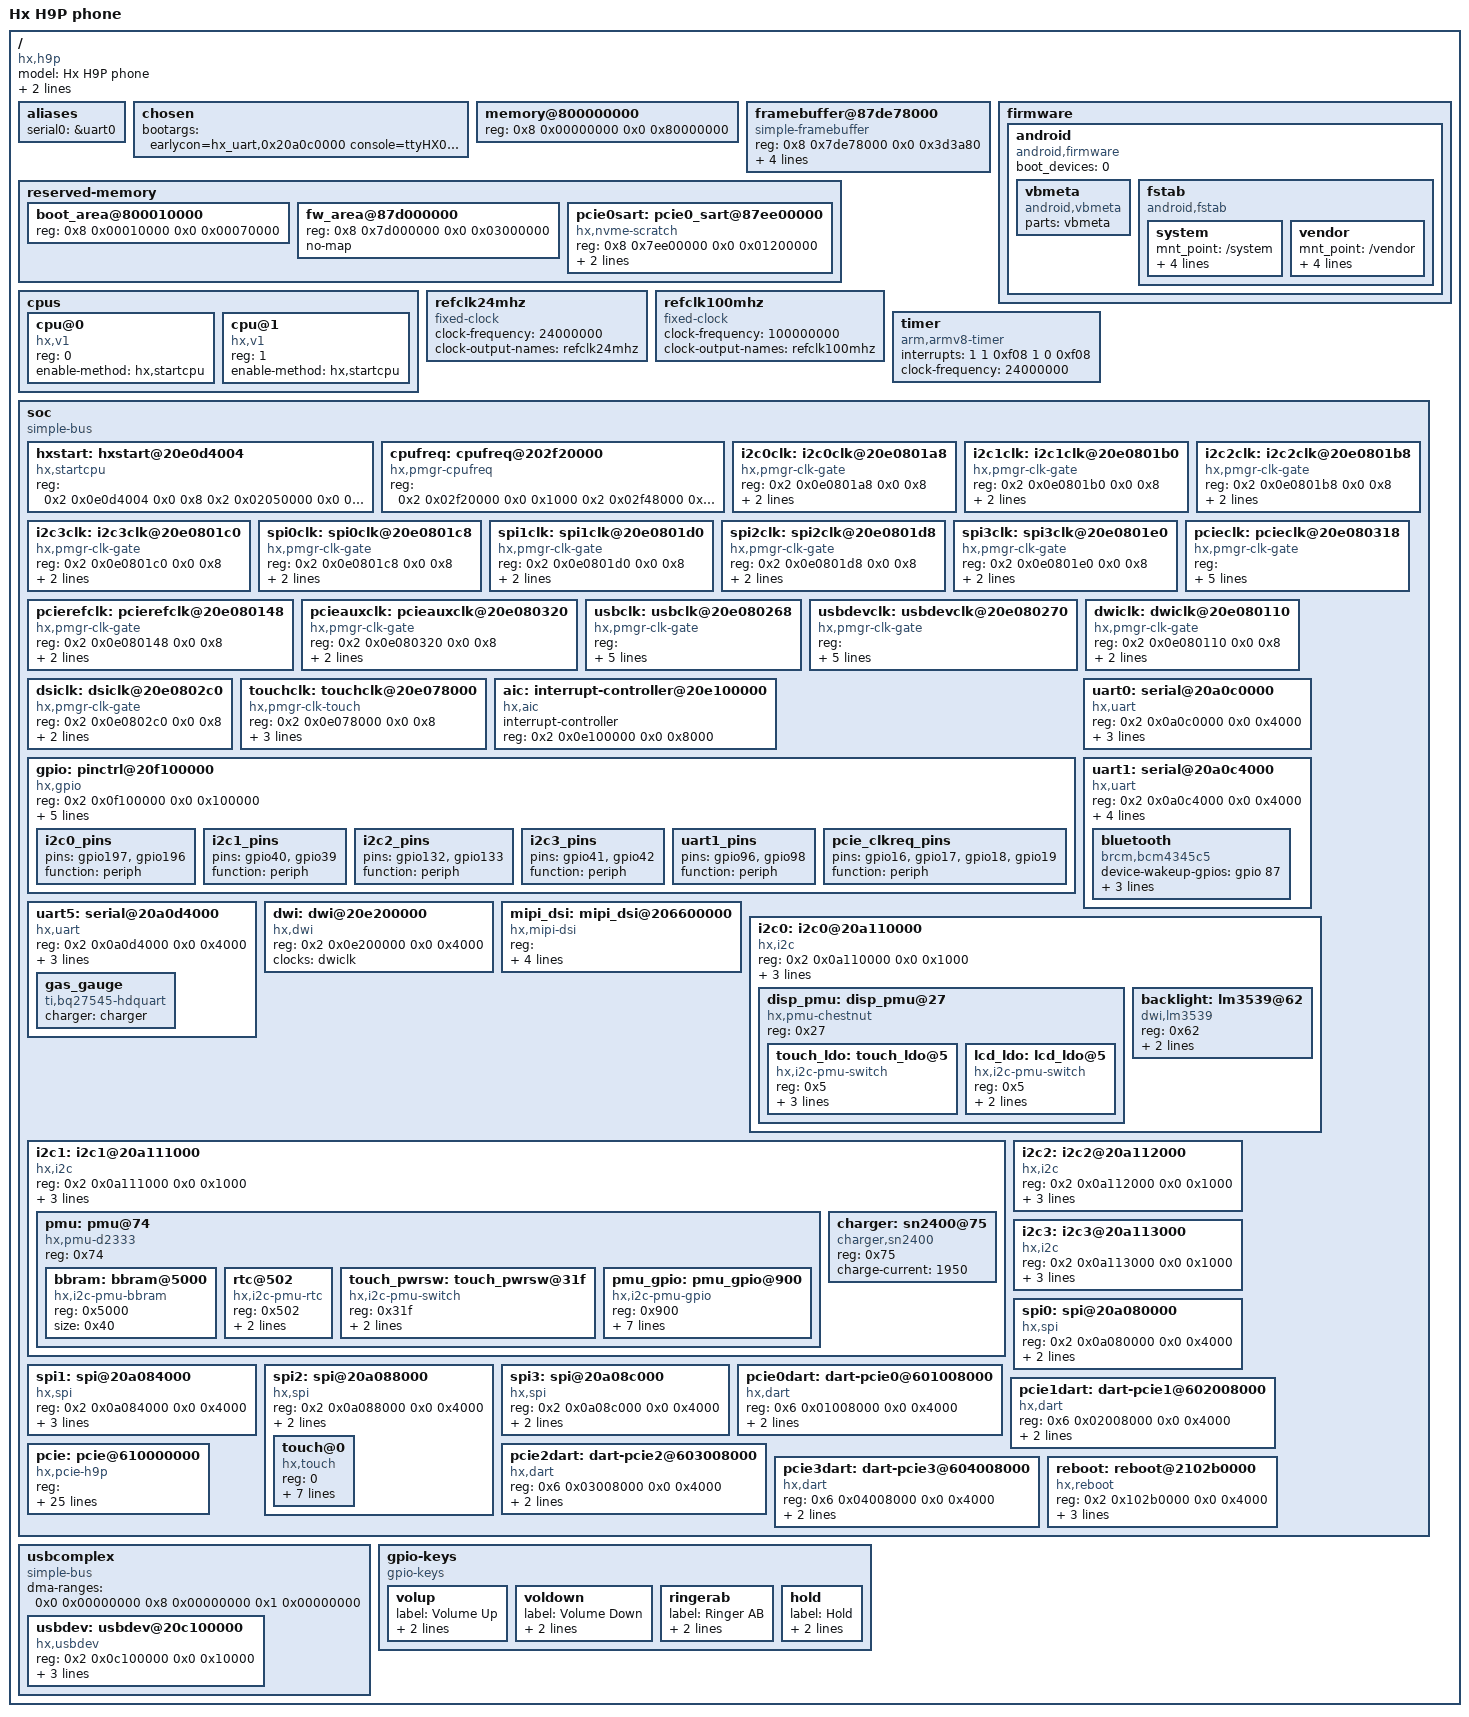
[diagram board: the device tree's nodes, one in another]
/dts-v1/;

/ {
    model = "Hx H9P phone";
    compatible = "hx,h9p";

    hardware-model = "D101";

    interrupt-parent = <&aic>;
    #address-cells = <2>;
    #size-cells = <2>;

    aliases {
        serial0 = &uart0;
    };

    chosen {
        bootargs = "earlycon=hx_uart,0x20a0c0000 console=ttyHX0 console=tty0 selinux=1 enforcing=0";
    };

    memory@800000000 {
        device_type = "memory";
        reg = <0x8 0x00000000 0x0 0x80000000>;
    };

    framebuffer@87de78000 {
        compatible = "simple-framebuffer";
        reg = <0x8 0x7de78000 0x0 0x3d3a80>;
        format = "a8b8g8r8";
        height = <0x536>;
        stride = <0xbc0>;
        width = <0x2ee>;
        status = "okay";
    };

    reserved-memory {
        #address-cells = <0x2>;
        #size-cells = <0x2>;
        ranges;

        boot_area@800010000 {
            reg = <0x8 0x00010000 0x0 0x00070000>;
        };

        fw_area@87d000000 {
            reg = <0x8 0x7d000000 0x0 0x03000000>;
            no-map;
        };

        pcie0sart: pcie0_sart@87ee00000 {
            compatible = "hx,nvme-scratch";
            reg = <0x8 0x7ee00000 0x0 0x01200000>;
            iova = <0xbc000000>;
            no-map;
        };
    };

    firmware {
        android {
            compatible = "android,firmware";
            boot_devices = "0";
//            boot_devices = "soc/610000000.pcie";

            vbmeta {
                compatible = "android,vbmeta";
                parts = "vbmeta";
            };

            fstab {
                compatible = "android,fstab";

                system {
                    mnt_point = "/system";
                    dev = "system";
                    type = "ext4";
                    mnt_flags = "ro";
                    fsmgr_flags = "wait,logical";
                    status = "ok";
                };

                vendor {
                    mnt_point = "/vendor";
                    dev = "vendor";
                    type = "ext4";
                    mnt_flags = "ro";
                    fsmgr_flags = "wait,logical";
                    status = "ok";
                };
            };
        };
    };

    cpus {
        #address-cells = <1>;
        #size-cells = <0>;

        cpu@0 {
            device_type = "cpu";
            compatible = "hx,v1";
            reg = <0>;
            enable-method = "hx,startcpu";
        };

        cpu@1 {
            device_type = "cpu";
            compatible = "hx,v1";
            reg = <1>;
            enable-method = "hx,startcpu";
        };
    };

    refclk24mhz: refclk24mhz {
        compatible = "fixed-clock";
        #clock-cells = <0>;
        clock-frequency = <24000000>;
        clock-output-names = "refclk24mhz";
    };

    refclk100mhz: refclk100mhz {
        compatible = "fixed-clock";
        #clock-cells = <0>;
        clock-frequency = <100000000>;
        clock-output-names = "refclk100mhz";
    };

    timer {
        compatible = "arm,armv8-timer";
        interrupts = <1 1 0xf08   1 0 0xf08>;
        clock-frequency = <24000000>;
    };

    soc {
        compatible = "simple-bus";
        #address-cells = <2>;
        #size-cells = <2>;
        ranges;

        hxstart: hxstart@20e0d4004 {
            compatible = "hx,startcpu";
            reg = <0x2 0x0e0d4004 0x0 0x8   0x2 0x02050000 0x0 0x8   0x2 0x02030fb0 0x0 0x4
                   0x2 0x0e0d4004 0x0 0x8   0x2 0x02150000 0x0 0x8   0x2 0x02130fb0 0x0 0x4>;
        };

        cpufreq: cpufreq@202f20000 {
            compatible = "hx,pmgr-cpufreq";
            reg = <0x2 0x02f20000 0x0 0x1000   0x2 0x02f48000 0x0 0x1000   0x2 0x02f50000 0x0 0x1000
                   0x2 0x02f80000 0x0 0x1000   0x2 0x0e068000 0x0 0x1000   0x2 0x0e09c000 0x0 0x1000
                   0x2 0x0e0a0000 0x0 0x1000   0x2 0x0e0c8000 0x0 0x1000>;
        };

        i2c0clk: i2c0clk@20e0801a8 {
            compatible = "hx,pmgr-clk-gate";
            #clock-cells = <0>;
            reg = <0x2 0x0e0801a8 0x0 0x8>;
            clocks = <&refclk24mhz>;
            clock-output-names = "i2c0clk";
        };

        i2c1clk: i2c1clk@20e0801b0 {
            compatible = "hx,pmgr-clk-gate";
            #clock-cells = <0>;
            reg = <0x2 0x0e0801b0 0x0 0x8>;
            clocks = <&refclk24mhz>;
            clock-output-names = "i2c1clk";
        };

        i2c2clk: i2c2clk@20e0801b8 {
            compatible = "hx,pmgr-clk-gate";
            #clock-cells = <0>;
            reg = <0x2 0x0e0801b8 0x0 0x8>;
            clocks = <&refclk24mhz>;
            clock-output-names = "i2c2clk";
        };

        i2c3clk: i2c3clk@20e0801c0 {
            compatible = "hx,pmgr-clk-gate";
            #clock-cells = <0>;
            reg = <0x2 0x0e0801c0 0x0 0x8>;
            clocks = <&refclk24mhz>;
            clock-output-names = "i2c3clk";
        };

        spi0clk: spi0clk@20e0801c8 {
            compatible = "hx,pmgr-clk-gate";
            #clock-cells = <0>;
            reg = <0x2 0x0e0801c8 0x0 0x8>;
            clocks = <&refclk24mhz>;
            clock-output-names = "spi0clk";
        };

        spi1clk: spi1clk@20e0801d0 {
            compatible = "hx,pmgr-clk-gate";
            #clock-cells = <0>;
            reg = <0x2 0x0e0801d0 0x0 0x8>;
            clocks = <&refclk24mhz>;
            clock-output-names = "spi1clk";
        };

        spi2clk: spi2clk@20e0801d8 {
            compatible = "hx,pmgr-clk-gate";
            #clock-cells = <0>;
            reg = <0x2 0x0e0801d8 0x0 0x8>;
            clocks = <&refclk24mhz>;
            clock-output-names = "spi2clk";
        };

        spi3clk: spi3clk@20e0801e0 {
            compatible = "hx,pmgr-clk-gate";
            #clock-cells = <0>;
            reg = <0x2 0x0e0801e0 0x0 0x8>;
            clocks = <&refclk24mhz>;
            clock-output-names = "spi3clk";
        };

        pcieclk: pcieclk@20e080318 {
            compatible = "hx,pmgr-clk-gate";
            #clock-cells = <0>;
            reg = <0x2 0x0e080318 0x0 0x8
                   0x6 0x00010000 0x0 0x8000>;
            clocks = <&refclk100mhz>;
            clock-output-names = "pcieclk";
            post-up = <1 0x0000 0x00000007   1 0x000c 0x80010005   1 0x4104 0x00000003   1 0x4100 0x00000003>;
        };

        pcierefclk: pcierefclk@20e080148 {
            compatible = "hx,pmgr-clk-gate";
            #clock-cells = <0>;
            reg = <0x2 0x0e080148 0x0 0x8>;
            clocks = <&refclk100mhz>;
            clock-output-names = "pcierefclk";
        };

        pcieauxclk: pcieauxclk@20e080320 {
            compatible = "hx,pmgr-clk-gate";
            #clock-cells = <0>;
            reg = <0x2 0x0e080320 0x0 0x8>;
            clocks = <&refclk100mhz>;
            clock-output-names = "pcieauxclk";
        };

        usbclk: usbclk@20e080268 {
            compatible = "hx,pmgr-clk-gate";
            #clock-cells = <0>;
            reg = <0x2 0x0e080268 0x0 0x8
                   0x2 0x0cb00000 0x0 0x20>;
            clocks = <&refclk24mhz>;
            clock-output-names = "usbclk";
            post-up = <1 0x00 0x00000000   1 0x04 0x00000000   1 0x08 0x00003f3f   1 0x0c 0x00003f3f   1 0x10 0x0000010c>;
        };

        usbdevclk: usbdevclk@20e080270 {
            compatible = "hx,pmgr-clk-gate";
            #clock-cells = <0>;
            reg = <0x2 0x0e080270 0x0 0x8
                   0x2 0x0c900000 0x0 0x100>;
            clocks = <&usbclk>;
            clock-output-names = "usbdevclk";
            post-up = <1 0x001c 0x00000108   1 0x003c 0x00000000   1 0x005c 0x00000108>; /* set DMA offsets for USB cores */
        };

        dwiclk: dwiclk@20e080110 {
            compatible = "hx,pmgr-clk-gate";
            #clock-cells = <0>;
            reg = <0x2 0x0e080110 0x0 0x8>;
            clocks = <&refclk24mhz>;
            clock-output-names = "dwiclk";
        };

        dsiclk: dsiclk@20e0802c0 {
            compatible = "hx,pmgr-clk-gate";
            #clock-cells = <0>;
            reg = <0x2 0x0e0802c0 0x0 0x8>;
            clocks = <&refclk100mhz>;
            clock-output-names = "dsiclk";
        };

        touchclk: touchclk@20e078000 {
            compatible = "hx,pmgr-clk-touch";
            #clock-cells = <0>;
            reg = <0x2 0x0e078000 0x0 0x8>;
            clocks = <&refclk24mhz>;
            clock-output-names = "touchclk";
            clock-frequency = <32768>;
        };

        aic: interrupt-controller@20e100000 {
            compatible = "hx,aic";
            #interrupt-cells = <3>;
            interrupt-controller;
            reg = <0x2 0x0e100000 0x0 0x8000>;
        };

        gpio: pinctrl@20f100000 {
            compatible = "hx,gpio";
            reg = <0x2 0x0f100000 0x0 0x100000>;
            pin-count = <224>;

            interrupts = <0 42 4   0 43 4   0 44 4   0 45 4   0 46 4   0 47 4   0 48 4>;

            gpio-controller;
            #gpio-cells = <2>;

            interrupt-controller;
            #interrupt-cells = <2>;

            i2c0_pins: i2c0_pins {
                pins = "gpio197", "gpio196";
                function = "periph";
            };

            i2c1_pins: i2c1_pins {
                pins = "gpio40", "gpio39";
                function = "periph";
            };

            i2c2_pins: i2c2_pins {
                pins = "gpio132", "gpio133";
                function = "periph";
            };

            i2c3_pins: i2c3_pins {
                pins = "gpio41", "gpio42";
                function = "periph";
            };

            uart1_pins: uart1_pins {
                pins = "gpio96", "gpio98";
                function = "periph";
            };

            pcie_clkreq_pins: pcie_clkreq_pins {
                pins = "gpio16", "gpio17", "gpio18", "gpio19";
                function = "periph";
            };
        };

        uart0: serial@20a0c0000 {
            compatible = "hx,uart";
            reg = <0x2 0x0a0c0000 0x0 0x4000>;
            interrupts = <0 218 4>;
            clocks = <&refclk24mhz>;
            clock-names = "refclk";
            index = <0>;
        };

        uart1: serial@20a0c4000 {
            compatible = "hx,uart";
            reg = <0x2 0x0a0c4000 0x0 0x4000>;
            interrupts = <0 219 4>;
            clocks = <&refclk24mhz>;
            clock-names = "refclk";
            index = <1>;
            pinctrl-0 = <&uart1_pins>;
            pinctrl-names = "default";

            bluetooth {
                compatible = "brcm,bcm4345c5";
                device-wakeup-gpios = <&gpio 87 0>;
                host-wakeup-gpios = <&pmu_gpio 11 0>;
                shutdown-gpios = <&pmu_gpio 8 0>;
                max-speed = <1500000>;
            };
        };

        uart5: serial@20a0d4000 {
            compatible = "hx,uart";
            reg = <0x2 0x0a0d4000 0x0 0x4000>;
            interrupts = <0 223 4>;
            clocks = <&refclk24mhz>;
            clock-names = "refclk";
            index = <5>;

            gas_gauge: gas_gauge {
                compatible = "ti,bq27545-hdquart";
                charger = <&charger>;
            };
        };

        dwi: dwi@20e200000 {
            compatible = "hx,dwi";
            reg = <0x2 0x0e200000 0x0 0x4000>;
            clocks = <&dwiclk>;
        };

        mipi_dsi: mipi_dsi@206600000 {
            compatible = "hx,mipi-dsi";
            reg = <0x2 0x06600000 0x0 0x100000   0x2 0x06400000 0x0 0x1000   0x2 0x0e0802c0 0x0 0x4>;
            clocks = <&dsiclk>;
            reset-gpios = <&gpio 172 0>;
            supply-name = "lcd_ldo";
        };

        i2c0: i2c0@20a110000 {
            compatible = "hx,i2c";
            reg = <0x2 0x0a110000 0x0 0x1000>;
            interrupts = <0 232 4>;
            clocks = <&i2c0clk>;
            pinctrl-0 = <&i2c0_pins>;
            pinctrl-names = "default";
            #address-cells = <0x1>;
            #size-cells = <0x0>;

            disp_pmu: disp_pmu@27 {
                compatible = "hx,pmu-chestnut";
                reg = <0x27>;
                #address-cells = <0x1>;
                #size-cells = <0x0>;

                touch_ldo: touch_ldo@5 {
                    compatible = "hx,i2c-pmu-switch";
                    reg = <0x5>;
                    mask = <0x10>;
                    enable = <0x10>;
                    supply-name = "mipi_dsi";
                };

                lcd_ldo: lcd_ldo@5 {
                    compatible = "hx,i2c-pmu-switch";
                    reg = <0x5>;
                    mask = <0x0F>;
                    enable = <0x0F>;
                };
            };

            backlight: lm3539@62 {
                compatible = "dwi,lm3539";
                reg = <0x62>;
                dwi = <&dwi>;
                lcd-supply = <&mipi_dsi>;
            };
        };

        i2c1: i2c1@20a111000 {
            compatible = "hx,i2c";
            reg = <0x2 0x0a111000 0x0 0x1000>;
            interrupts = <0 233 4>;
            clocks = <&i2c1clk>;
            pinctrl-0 = <&i2c1_pins>;
            pinctrl-names = "default";
            #address-cells = <0x1>;
            #size-cells = <0x0>;

            pmu: pmu@74 {
                compatible = "hx,pmu-d2333";
                reg = <0x74>;
                #address-cells = <0x1>;
                #size-cells = <0x0>;

                bbram: bbram@5000 {
                    compatible = "hx,i2c-pmu-bbram";
                    reg = <0x5000>;
                    size = <0x40>;
                };

                rtc@502 {
                    compatible = "hx,i2c-pmu-rtc";
                    reg = <0x502>;
                    nvmem = <&bbram>;
                    nvmem-offset = <0x4>;
                };

                touch_pwrsw: touch_pwrsw@31f {
                    compatible = "hx,i2c-pmu-switch";
                    reg = <0x31f>;
                    mask = <0x1>;
                    enable = <0x1>;
                };

                pmu_gpio: pmu_gpio@900 {
                    compatible = "hx,i2c-pmu-gpio";
                    reg = <0x900>;
                    reg-offs = <0x00 0x02 0x04 0x06 0x08 0x0a 0x0c 0x0e
                                0x10 0x12 0x14 0x16 0x18 0x1a 0x1c 0x1e
                                0x20 0x27 0x2d 0x33 0x39>;
                    reg-input = <0x186>;
                    bit-outval = <0x01 0x01>;
                    bit-direction = <0xc0 0x00 0x80>;

                    gpio-controller;
                    #gpio-cells = <2>;
                    gpio-base = <224>;
                };
            };

            charger: sn2400@75 {
                compatible = "charger,sn2400";
                reg = <0x75>;
                charge-current = <1950>;
            };
        };

        i2c2: i2c2@20a112000 {
            compatible = "hx,i2c";
            reg = <0x2 0x0a112000 0x0 0x1000>;
            interrupts = <0 234 4>;
            clocks = <&i2c2clk>;
            pinctrl-0 = <&i2c2_pins>;
            pinctrl-names = "default";
            #address-cells = <0x1>;
            #size-cells = <0x0>;
        };

        i2c3: i2c3@20a113000 {
            compatible = "hx,i2c";
            reg = <0x2 0x0a113000 0x0 0x1000>;
            interrupts = <0 235 4>;
            clocks = <&i2c3clk>;
            pinctrl-0 = <&i2c3_pins>;
            pinctrl-names = "default";
            #address-cells = <0x1>;
            #size-cells = <0x0>;
        };

        spi0: spi@20a080000 {
            compatible = "hx,spi";
            reg = <0x2 0x0a080000 0x0 0x4000>;
            interrupts = <0 214 4>;
            clocks = <&spi0clk>;
            #address-cells = <1>;
            #size-cells = <0>;
        };

        spi1: spi@20a084000 {
            compatible = "hx,spi";
            reg = <0x2 0x0a084000 0x0 0x4000>;
            interrupts = <0 215 4>;
            clocks = <&spi1clk>;
            cs-gpios = <&gpio 131 0   &gpio 177 0>;
            #address-cells = <1>;
            #size-cells = <0>;
        };

        spi2: spi@20a088000 {
            compatible = "hx,spi";
            reg = <0x2 0x0a088000 0x0 0x4000>;
            interrupts = <0 216 4>;
            clocks = <&spi2clk>;
            #address-cells = <1>;
            #size-cells = <0>;

            touch@0 {
                compatible = "hx,touch";
                reg = <0>;
                spi-max-frequency = <3000000>;
                hv-supply = <&touch_ldo>;
                core-supply = <&touch_pwrsw>;
                reset-gpios = <&gpio 161 0>;
                cs-gpios = <&gpio 81 0>;
                irq-gpios = <&gpio 166 1>;
                clocks = <&touchclk>;
            };
        };

        spi3: spi@20a08c000 {
            compatible = "hx,spi";
            reg = <0x2 0x0a08c000 0x0 0x4000>;
            interrupts = <0 217 4>;
            clocks = <&spi3clk>;
            #address-cells = <1>;
            #size-cells = <0>;
        };

        pcie0dart: dart-pcie0@601008000 {
            compatible = "hx,dart";
            reg = <0x6 0x01008000 0x0 0x4000>;
            interrupts = <0 271 4>;
            pcie-dart;
            #iommu-cells = <1>;
        };

        pcie1dart: dart-pcie1@602008000 {
            compatible = "hx,dart";
            reg = <0x6 0x02008000 0x0 0x4000>;
            interrupts = <0 274 4>;
            pcie-dart;
            #iommu-cells = <1>;
        };

        pcie2dart: dart-pcie2@603008000 {
            compatible = "hx,dart";
            reg = <0x6 0x03008000 0x0 0x4000>;
            interrupts = <0 277 4>;
            pcie-dart;
            #iommu-cells = <1>;
        };

        pcie3dart: dart-pcie3@604008000 {
            compatible = "hx,dart";
            reg = <0x6 0x04008000 0x0 0x4000>;
            interrupts = <0 280 4>;
            pcie-dart;
            #iommu-cells = <1>;
        };

        pcie: pcie@610000000 {
            compatible = "hx,pcie-h9p";
            reg = <0x6 0x10000000 0x0 0x1000000                                                                 /* config */
                   0x6 0x00000000 0x0 0x8000   0x6 0x00008000 0x0 0x4000   0x6 0x0a000000 0x0 0x40000           /* PHY and link */
                   0x6 0x01000000 0x0 0x4000   0x6 0x02000000 0x0 0x4000                                        /* ports */
                   0x6 0x03000000 0x0 0x4000   0x6 0x04000000 0x0 0x4000
                   0x6 0x01004000 0x0 0x4000>;                                                                  /* SART */
            interrupt-parent = <&aic>;
            interrupts = <0 270 4   0 273 4   0 276 4   0 279 4                                                 /* state */
                          0 288 1   0 289 1   0 290 1   0 291 1   0 292 1   0 293 1   0 294 1   0 295 1         /* MSI */
                          0 296 1   0 297 1   0 298 1   0 299 1   0 300 1   0 301 1   0 302 1   0 303 1
                          0 304 1   0 305 1   0 306 1   0 307 1   0 308 1   0 309 1   0 310 1   0 311 1
                          0 312 1   0 313 1   0 314 1   0 315 1   0 316 1   0 317 1   0 318 1   0 319 1
                          0 272 1>;                                                                             /* SART */
            clocks = <&pcieclk &pcieauxclk &pcierefclk>;
            clock-names = "core", "aux", "ref";
            pinctrl-0 = <&pcie_clkreq_pins>;
            pinctrl-names = "default";
            perst-gpios = <&gpio 12 0   &gpio 13 0   &gpio 14 0   &gpio 15 0>;
            clkreq-gpios = <&gpio 16 0   &gpio 17 0   &gpio 18 0   &gpio 19 0>;
            debug-gpios = <&gpio 206 0>;
            #address-cells = <3>;
            #size-cells = <2>;
            #interrupt-cells = <1>;
            device_type = "pci";
            msi-controller;
            msi-parent = <&pcie>;
            msi-doorbell = <0x0 0xbffff000>;
            ranges = <0x03000000   0x0 0xc0000000   0x7 0xc0000000 0x0 0x40000000>;
            bus-range = <0x00 0x0f>;
            iommu-map = <0x0000 &pcie0dart 0x8000 0x0100>, /* fake, and should never be used as RC bridges don't DMA */
                        <0x0100 &pcie0dart 0x0000 0x0100>,
                        <0x0200 &pcie1dart 0x0000 0x0100>,
                        <0x0300 &pcie2dart 0x0000 0x0100>,
                        <0x0400 &pcie3dart 0x0000 0x0100>;
            sart-regions = <&pcie0sart>;
            sart-map = <1 0 0 0>;
            devpwr-gpios = <&gpio 88 0  &pmu_gpio 10 0>;
            devpwr-on-0 = <>;
            devpwr-on-3 = <0 0   1 0   0 1   1 1>; /* 3 for D10ap, 2 for D101ap */
        };

        reboot: reboot@2102b0000 {
            compatible = "hx,reboot";
            reg = <0x2 0x102b0000 0x0 0x4000>;
            nvmem = <&bbram>;
            nvmem-poweroff = <0x1 0xff 0x00   0x2 0xff 0x00   0x3 0xff 0x00   0xf 0xf0 0x90>;
        };
    };

    usbcomplex {
        compatible = "simple-bus";
        #address-cells = <2>;
        #size-cells = <2>;
        dma-ranges = <0x0 0x00000000 0x8 0x00000000 0x1 0x00000000>;
        ranges;

        usbdev: usbdev@20c100000 {
            compatible = "hx,usbdev";
            reg = <0x2 0x0c100000 0x0 0x10000>;
            interrupts = <0 241 4>;
            clocks = <&usbdevclk>;
            clock-names = "otg";
            hx,dma-remap;
        };
    };

    gpio-keys {
        compatible = "gpio-keys";

        volup {
            label = "Volume Up";
            gpios = <&gpio 23 1>;
            linux,code = <115>;
        };

        voldown {
            label = "Volume Down";
            gpios = <&gpio 180 1>;
            linux,code = <114>;
        };

        ringerab {
            label = "Ringer AB";
            gpios = <&gpio 86 1>;
            linux,code = <113>;
        };

        hold {
            label = "Hold";
            gpios = <&gpio 179 1>;
            linux,code = <116>;
        };
    };
};
